AUTOSAR XML (schema 4-2-2)
package /STELLANTIS/EPT/ASWCs
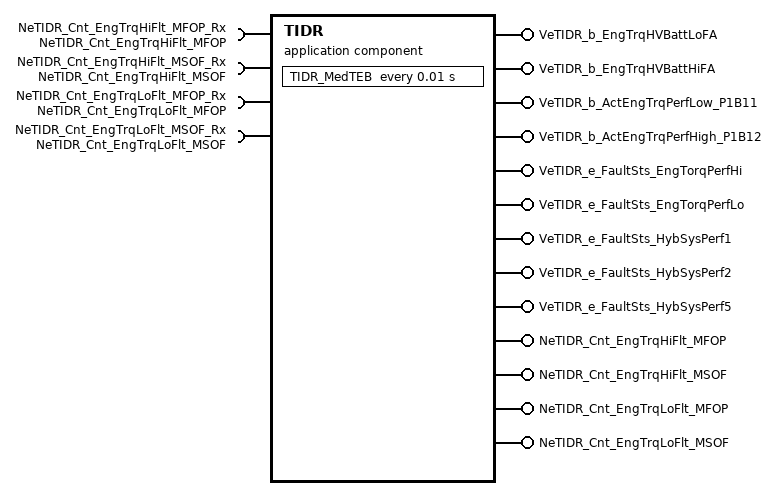
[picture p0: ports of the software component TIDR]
  application sw component type TIDR
    9 x provide port:
      VeTIDR_b_EngTrqHVBattLoFA: nonqueued-sender-com-spec{data-element=Value, init-value=0}, provided-interface=VeTIDR_b_EngTrqHVBattLoFA
      VeTIDR_b_EngTrqHVBattHiFA: nonqueued-sender-com-spec{data-element=Value, init-value=0}, provided-interface=VeTIDR_b_EngTrqHVBattHiFA
      VeTIDR_b_ActEngTrqPerfLow_P1B11: nonqueued-sender-com-spec{data-element=Value, init-value=0}, provided-interface=VeTIDR_b_ActEngTrqPerfLow_P1B11
      VeTIDR_b_ActEngTrqPerfHigh_P1B12: nonqueued-sender-com-spec{data-element=Value, init-value=0}, provided-interface=VeTIDR_b_ActEngTrqPerfHigh_P1B12
      VeTIDR_e_FaultSts_EngTorqPerfHi: nonqueued-sender-com-spec{data-element=Value, init-value=CeDFIB_e_Init}, provided-interface=VeTIDR_e_FaultSts_EngTorqPerfHi
      VeTIDR_e_FaultSts_EngTorqPerfLo: nonqueued-sender-com-spec{data-element=Value, init-value=CeDFIB_e_Init}, provided-interface=VeTIDR_e_FaultSts_EngTorqPerfLo
      VeTIDR_e_FaultSts_HybSysPerf1: nonqueued-sender-com-spec{data-element=Value, init-value=CeDFIB_e_Init}, provided-interface=VeTIDR_e_FaultSts_HybSysPerf1
      VeTIDR_e_FaultSts_HybSysPerf2: nonqueued-sender-com-spec{data-element=Value, init-value=CeDFIB_e_Init}, provided-interface=VeTIDR_e_FaultSts_HybSysPerf2
      VeTIDR_e_FaultSts_HybSysPerf5: nonqueued-sender-com-spec{data-element=Value, init-value=CeDFIB_e_Init}, provided-interface=VeTIDR_e_FaultSts_HybSysPerf5
    4 x require port:
      NeTIDR_Cnt_EngTrqHiFlt_MFOP_Rx: nv-require-com-spec{init-value=0, variable=NeTIDR_Cnt_EngTrqHiFlt_MFOP}, required-interface=NeTIDR_Cnt_EngTrqHiFlt_MFOP
      NeTIDR_Cnt_EngTrqHiFlt_MSOF_Rx: nv-require-com-spec{init-value=0, variable=NeTIDR_Cnt_EngTrqHiFlt_MSOF}, required-interface=NeTIDR_Cnt_EngTrqHiFlt_MSOF
      NeTIDR_Cnt_EngTrqLoFlt_MFOP_Rx: nv-require-com-spec{init-value=0, variable=NeTIDR_Cnt_EngTrqLoFlt_MFOP}, required-interface=NeTIDR_Cnt_EngTrqLoFlt_MFOP
      NeTIDR_Cnt_EngTrqLoFlt_MSOF_Rx: nv-require-com-spec{init-value=0, variable=NeTIDR_Cnt_EngTrqLoFlt_MSOF}, required-interface=NeTIDR_Cnt_EngTrqLoFlt_MSOF
    4 x provide port:
      NeTIDR_Cnt_EngTrqHiFlt_MFOP: nv-provide-com-spec{ram-block-init-value=0, variable=NeTIDR_Cnt_EngTrqHiFlt_MFOP}, provided-interface=NeTIDR_Cnt_EngTrqHiFlt_MFOP
      NeTIDR_Cnt_EngTrqHiFlt_MSOF: nv-provide-com-spec{ram-block-init-value=0, variable=NeTIDR_Cnt_EngTrqHiFlt_MSOF}, provided-interface=NeTIDR_Cnt_EngTrqHiFlt_MSOF
      NeTIDR_Cnt_EngTrqLoFlt_MFOP: nv-provide-com-spec{ram-block-init-value=0, variable=NeTIDR_Cnt_EngTrqLoFlt_MFOP}, provided-interface=NeTIDR_Cnt_EngTrqLoFlt_MFOP
      NeTIDR_Cnt_EngTrqLoFlt_MSOF: nv-provide-com-spec{ram-block-init-value=0, variable=NeTIDR_Cnt_EngTrqLoFlt_MSOF}, provided-interface=NeTIDR_Cnt_EngTrqLoFlt_MSOF
    behavior IB_TIDR: data-type-mapping=msADTtoIDTMapping, handle-termination-and-restart=NO-SUPPORT
      timing event Event_MedTEB: start-on-event=TIDR_MedTEB, period=0.01
      init event Event_TIDR_ac_Init: start-on-event=TIDR_ac_Init
      init event Event_PwrOn: start-on-event=TIDR_PwrOn
      init event Event_PwrOff: start-on-event=TIDR_PwrOff
      4 x runnable:
        TIDR_ac_Init
          data-send-points:
            9 x access:
              OUT_VeTIDR_b_EngTrqHVBattLoFA_Value: accessed-variable=VeTIDR_b_EngTrqHVBattLoFA.Value
              OUT_VeTIDR_b_EngTrqHVBattHiFA_Value: accessed-variable=VeTIDR_b_EngTrqHVBattHiFA.Value
              OUT_VeTIDR_b_ActEngTrqPerfLow_P1B11_Value: accessed-variable=VeTIDR_b_ActEngTrqPerfLow_P1B11.Value
              OUT_VeTIDR_b_ActEngTrqPerfHigh_P1B12_Value: accessed-variable=VeTIDR_b_ActEngTrqPerfHigh_P1B12.Value
              OUT_VeTIDR_e_FaultSts_EngTorqPerfHi_Value: accessed-variable=VeTIDR_e_FaultSts_EngTorqPerfHi.Value
              OUT_VeTIDR_e_FaultSts_EngTorqPerfLo_Value: accessed-variable=VeTIDR_e_FaultSts_EngTorqPerfLo.Value
              OUT_VeTIDR_e_FaultSts_HybSysPerf1_Value: accessed-variable=VeTIDR_e_FaultSts_HybSysPerf1.Value
              OUT_VeTIDR_e_FaultSts_HybSysPerf2_Value: accessed-variable=VeTIDR_e_FaultSts_HybSysPerf2.Value
              OUT_VeTIDR_e_FaultSts_HybSysPerf5_Value: accessed-variable=VeTIDR_e_FaultSts_HybSysPerf5.Value
        TIDR_MedTEB
          data-send-points:
            9 x access:
              OUT_VeTIDR_b_EngTrqHVBattLoFA_Value: accessed-variable=VeTIDR_b_EngTrqHVBattLoFA.Value
              OUT_VeTIDR_b_EngTrqHVBattHiFA_Value: accessed-variable=VeTIDR_b_EngTrqHVBattHiFA.Value
              OUT_VeTIDR_b_ActEngTrqPerfLow_P1B11_Value: accessed-variable=VeTIDR_b_ActEngTrqPerfLow_P1B11.Value
              OUT_VeTIDR_b_ActEngTrqPerfHigh_P1B12_Value: accessed-variable=VeTIDR_b_ActEngTrqPerfHigh_P1B12.Value
              OUT_VeTIDR_e_FaultSts_EngTorqPerfHi_Value: accessed-variable=VeTIDR_e_FaultSts_EngTorqPerfHi.Value
              OUT_VeTIDR_e_FaultSts_EngTorqPerfLo_Value: accessed-variable=VeTIDR_e_FaultSts_EngTorqPerfLo.Value
              OUT_VeTIDR_e_FaultSts_HybSysPerf1_Value: accessed-variable=VeTIDR_e_FaultSts_HybSysPerf1.Value
              OUT_VeTIDR_e_FaultSts_HybSysPerf2_Value: accessed-variable=VeTIDR_e_FaultSts_HybSysPerf2.Value
              OUT_VeTIDR_e_FaultSts_HybSysPerf5_Value: accessed-variable=VeTIDR_e_FaultSts_HybSysPerf5.Value
        TIDR_PwrOn
          data-receive-point-by-arguments:
            4 x access:
              IN_NeTIDR_Cnt_EngTrqHiFlt_MFOP_Rx_NeTIDR_Cnt_EngTrqHiFlt_MFOP: accessed-variable=NeTIDR_Cnt_EngTrqHiFlt_MFOP_Rx.NeTIDR_Cnt_EngTrqHiFlt_MFOP
              IN_NeTIDR_Cnt_EngTrqHiFlt_MSOF_Rx_NeTIDR_Cnt_EngTrqHiFlt_MSOF: accessed-variable=NeTIDR_Cnt_EngTrqHiFlt_MSOF_Rx.NeTIDR_Cnt_EngTrqHiFlt_MSOF
              IN_NeTIDR_Cnt_EngTrqLoFlt_MFOP_Rx_NeTIDR_Cnt_EngTrqLoFlt_MFOP: accessed-variable=NeTIDR_Cnt_EngTrqLoFlt_MFOP_Rx.NeTIDR_Cnt_EngTrqLoFlt_MFOP
              IN_NeTIDR_Cnt_EngTrqLoFlt_MSOF_Rx_NeTIDR_Cnt_EngTrqLoFlt_MSOF: accessed-variable=NeTIDR_Cnt_EngTrqLoFlt_MSOF_Rx.NeTIDR_Cnt_EngTrqLoFlt_MSOF
          data-send-points:
            9 x access:
              OUT_VeTIDR_b_EngTrqHVBattLoFA_Value: accessed-variable=VeTIDR_b_EngTrqHVBattLoFA.Value
              OUT_VeTIDR_b_EngTrqHVBattHiFA_Value: accessed-variable=VeTIDR_b_EngTrqHVBattHiFA.Value
              OUT_VeTIDR_b_ActEngTrqPerfLow_P1B11_Value: accessed-variable=VeTIDR_b_ActEngTrqPerfLow_P1B11.Value
              OUT_VeTIDR_b_ActEngTrqPerfHigh_P1B12_Value: accessed-variable=VeTIDR_b_ActEngTrqPerfHigh_P1B12.Value
              OUT_VeTIDR_e_FaultSts_EngTorqPerfHi_Value: accessed-variable=VeTIDR_e_FaultSts_EngTorqPerfHi.Value
              OUT_VeTIDR_e_FaultSts_EngTorqPerfLo_Value: accessed-variable=VeTIDR_e_FaultSts_EngTorqPerfLo.Value
              OUT_VeTIDR_e_FaultSts_HybSysPerf1_Value: accessed-variable=VeTIDR_e_FaultSts_HybSysPerf1.Value
              OUT_VeTIDR_e_FaultSts_HybSysPerf2_Value: accessed-variable=VeTIDR_e_FaultSts_HybSysPerf2.Value
              OUT_VeTIDR_e_FaultSts_HybSysPerf5_Value: accessed-variable=VeTIDR_e_FaultSts_HybSysPerf5.Value
        TIDR_PwrOff
          data-send-points:
            4 x access:
              OUT_NeTIDR_Cnt_EngTrqHiFlt_MFOP_NeTIDR_Cnt_EngTrqHiFlt_MFOP: accessed-variable=NeTIDR_Cnt_EngTrqHiFlt_MFOP.NeTIDR_Cnt_EngTrqHiFlt_MFOP
              OUT_NeTIDR_Cnt_EngTrqHiFlt_MSOF_NeTIDR_Cnt_EngTrqHiFlt_MSOF: accessed-variable=NeTIDR_Cnt_EngTrqHiFlt_MSOF.NeTIDR_Cnt_EngTrqHiFlt_MSOF
              OUT_NeTIDR_Cnt_EngTrqLoFlt_MFOP_NeTIDR_Cnt_EngTrqLoFlt_MFOP: accessed-variable=NeTIDR_Cnt_EngTrqLoFlt_MFOP.NeTIDR_Cnt_EngTrqLoFlt_MFOP
              OUT_NeTIDR_Cnt_EngTrqLoFlt_MSOF_NeTIDR_Cnt_EngTrqLoFlt_MSOF: accessed-variable=NeTIDR_Cnt_EngTrqLoFlt_MSOF.NeTIDR_Cnt_EngTrqLoFlt_MSOF
      variation point proxy Variant_TIDR_1: category=CONDITION, condition-access=0
      variation point proxy Variant_TIDR_2: category=CONDITION, condition-access=0
